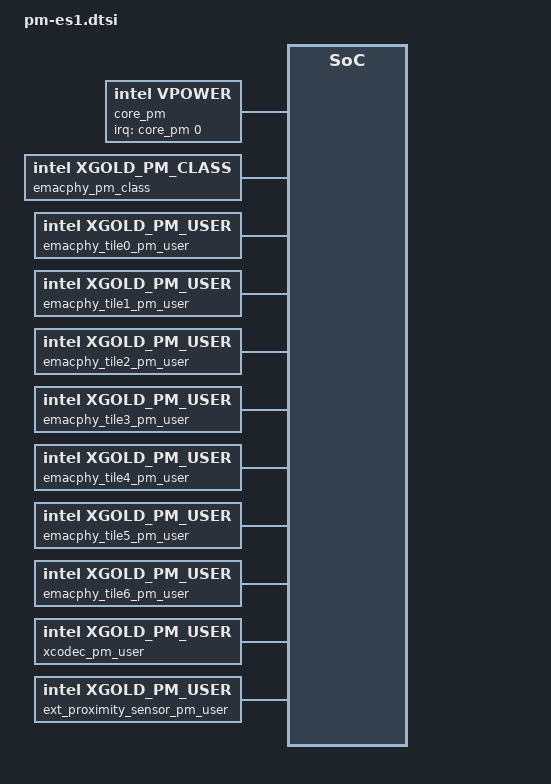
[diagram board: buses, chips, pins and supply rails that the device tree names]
#include "prh_cfg-es1.h"

core_pm:core_pm {
	compatible = "intel,vpower";
	intel,prh_mode = "async";

	#address-cells = < 0 >;
	interrupts = < 0 >;
	interrupt-parent = <&core_pm>;
	#interrupt-cells = < 1 >;
	interrupt-map = < 0 &hirq HIRQ_PMIC_PRH_SIGNALING IRQ_TYPE_DEFAULT>;
	interrupt-names = "notification";
};

generic_pm_class:generic_pm_class {
	compatible = "intel,xgold_pm_class";
	intel,name = "generic_class";
	intel,sync = < 0 0 0 >;
	intel,states-names =
		"disable",
		"enable";
	intel,states = <
		PRH_PER_TYPE_GENERIC PRH_PER_GENERIC_DISABLE
		PRH_PER_TYPE_GENERIC PRH_PER_GENERIC_ENABLE >;
};

mmc_core_clk_pm_class:mmc_core_clk_pm_class {
	compatible = "intel,xgold_pm_class";
	intel,name = "mmc_core_clk_class";
	intel,sync = < 0 0 0 >;
	intel,states-names =
		"low_perf",
		"med_perf",
		"high_perf";
	intel,states = <
		PRH_PER_TYPE_MMC_CORE_CLK PRH_PER_MMC_CORE_CLK_ENABLE_LOW_PERF
		PRH_PER_TYPE_MMC_CORE_CLK PRH_PER_MMC_CORE_CLK_ENABLE_MED_PERF
		PRH_PER_TYPE_MMC_CORE_CLK PRH_PER_MMC_CORE_CLK_ENABLE_HIGH_PERF >;
};

_3g_comram_pm_class:_3g_comram_pm_class {
	compatible = "intel,xgold_pm_class";
	intel,name = "_3g_comram_class";
	intel,sync = < 0 0 0 >;
	intel,states-names =
		"disable",
		"enable",
		"shutdown";
	intel,states = <
		PRH_PER_TYPE_3G_COMRAM PRH_PER_3G_COMRAM_DISABLE
		PRH_PER_TYPE_3G_COMRAM PRH_PER_3G_COMRAM_ENABLE
		PRH_PER_TYPE_3G_COMRAM PRH_PER_3G_COMRAM_SHUTDOWN >;
};

emacphy_pm_class:emacphy_pm_class {
	compatible = "intel,xgold_pm_class";
	intel,name = "emacphy_class";
	intel,sync = < 0 0 0 >;
	intel,states-names =
		"disable",
		"low_perf",
		"mid_perf",
		"high_perf",
		"reset",
		"low_perf_3g";
	intel,states = <
		PRH_PER_TYPE_EMACPHY PRH_PER_EMACPHY_DISABLE
		PRH_PER_TYPE_EMACPHY PRH_PER_EMACPHY_ENABLE_LOW_PERF
		PRH_PER_TYPE_EMACPHY PRH_PER_EMACPHY_ENABLE_MID_PERF
		PRH_PER_TYPE_EMACPHY PRH_PER_EMACPHY_ENABLE_HIGH_PERF
		PRH_PER_TYPE_EMACPHY PRH_PER_EMACPHY_RESET
		PRH_PER_TYPE_EMACPHY PRH_PER_EMACPHY_ENABLE_LOW_PERF_3G >;
};

dma_pm_class:dma_pm_class {
	compatible = "intel,xgold_pm_class";
	intel,name = "dma_class";
	intel,sync = < 0 0 0 >;
	intel,states-names =
		"disable",
		"low_perf",
		"med_perf",
		"high_perf";
	intel,states = <
		PRH_PER_TYPE_DMA PRH_PER_DMA_DISABLE
		PRH_PER_TYPE_DMA PRH_PER_DMA_ENABLE_LOW_PERF
		PRH_PER_TYPE_DMA PRH_PER_DMA_ENABLE_MED_PERF
		PRH_PER_TYPE_DMA PRH_PER_DMA_ENABLE_HIGH_PERF >;
};

dsp_pm_class:dsp_pm_class {
	compatible = "intel,xgold_pm_class";
	intel,name = "dsp_class";
	intel,sync = < 0 0 0 >;
	intel,states-names =
		"disable",
		"enable",
		"suspend",
		"shutdown";
	intel,states = <
		PRH_PER_TYPE_DSP PRH_PER_DSP_DISABLE
		PRH_PER_TYPE_DSP PRH_PER_DSP_ENABLE
		PRH_PER_TYPE_DSP PRH_PER_DSP_SUSPEND
		PRH_PER_TYPE_DSP PRH_PER_DSP_SHUTDOWN >;
};

i2c_pm_class:i2c_pm_class {
	compatible = "intel,xgold_pm_class";
	intel,name = "i2c_class";
	intel,sync = < 0 0 0 >;
	intel,states-names =
		"disable",
		"enable",
		"psv";
	intel,states = <
		PRH_PER_TYPE_I2C PRH_PER_I2C_DISABLE
		PRH_PER_TYPE_I2C PRH_PER_I2C_ENABLE
		PRH_PER_TYPE_I2C PRH_PER_I2C_ENABLE_PSV >;
};

mmcsd_volt_pm_class:mmcsd_volt_pm_class {
	compatible = "intel,xgold_pm_class";
	intel,name = "mmcsd_volt_class";
	intel,sync = < 0 0 0 >;
	intel,states-names =
		"disable",
		"low_perf",
		"mid_perf",
		"high_perf";
	intel,states = <
		PRH_PER_TYPE_MMCSD_VOLT PRH_PER_MMCSD_VOLT_DISABLE
		PRH_PER_TYPE_MMCSD_VOLT PRH_PER_MMCSD_VOLT_ENABLE_LOW
		PRH_PER_TYPE_MMCSD_VOLT PRH_PER_MMCSD_VOLT_ENABLE_MID
		PRH_PER_TYPE_MMCSD_VOLT PRH_PER_MMCSD_VOLT_ENABLE_HIGH >;
};

mmcsd_clk_pm_class:mmcsd_clk_pm_class {
	compatible = "intel,xgold_pm_class";
	intel,name = "mmcsd_clk_class";
	intel,sync = < 0 0 0 >;
	intel,states-names =
		"disable",
		"low_perf",
		"mid_perf",
		"high_perf";
	intel,states = <
		PRH_PER_TYPE_MMCSD_CLK PRH_PER_MMCSD_CLK_DISABLE
		PRH_PER_TYPE_MMCSD_CLK PRH_PER_MMCSD_CLK_ENABLE_LOW
		PRH_PER_TYPE_MMCSD_CLK PRH_PER_MMCSD_CLK_ENABLE_MID
		PRH_PER_TYPE_MMCSD_CLK PRH_PER_MMCSD_CLK_ENABLE_HIGH >;
};

usb_pm_class:usb_pm_class {
	compatible = "intel,xgold_pm_class";
	intel,name = "usb_class";
	intel,sync = < 0 0 0 >;
	intel,states-names =
		"disable",
		"suspend",
		"suspend_no_psv",
		"enable";
	intel,states = <
		PRH_PER_TYPE_USB PRH_PER_USB_DISABLE
		PRH_PER_TYPE_USB PRH_PER_USB_SUSPEND
		PRH_PER_TYPE_USB PRH_PER_USB_SUSPEND_NO_PSV
		PRH_PER_TYPE_USB PRH_PER_USB_ENABLE >;
};

usif_pm_class:usif_pm_class {
	compatible = "intel,xgold_pm_class";
	intel,name = "usif_class";
	intel,sync = < 0 0 0 >;
	intel,states-names =
		"disable",
		"enable_26M",
		"enable_26M_hperf",
		"enable_96M",
		"enable_96M_hperf",
		"enable_104M",
		"enable_104M_hperf";
	intel,states  = <
		PRH_PER_TYPE_USIF PRH_PER_USIF_DISABLE PRH_PER_USIF_CLK_DONT_CARE 0
		PRH_PER_TYPE_USIF PRH_PER_USIF_ENABLE PRH_PER_USIF_CLK_26MHZ 0
		PRH_PER_TYPE_USIF PRH_PER_USIF_ENABLE PRH_PER_USIF_CLK_26MHZ 3173
		PRH_PER_TYPE_USIF PRH_PER_USIF_ENABLE PRH_PER_USIF_CLK_96MHZ 0
		PRH_PER_TYPE_USIF PRH_PER_USIF_ENABLE PRH_PER_USIF_CLK_96MHZ 3173
		PRH_PER_TYPE_USIF PRH_PER_USIF_ENABLE PRH_PER_USIF_CLK_104MHZ 0
		PRH_PER_TYPE_USIF PRH_PER_USIF_ENABLE PRH_PER_USIF_CLK_104MHZ 3173 >;
};

capcom_pm_class:capcom_pm_class {
	compatible = "intel,xgold_pm_class";
	intel,name = "capcom_class";
	intel,sync = < 0 0 0 >;
	intel,states-names =
		"disable",
		"enable",
		"disable_psv",
		"psv";
	intel,states = <
		PRH_PER_TYPE_CAPCOM PRH_PER_CAPCOM_DISABLE
		PRH_PER_TYPE_CAPCOM PRH_PER_CAPCOM_ENABLE
		PRH_PER_TYPE_CAPCOM PRH_PER_CAPCOM_DISABLE_PSV
		PRH_PER_TYPE_CAPCOM PRH_PER_CAPCOM_ENABLE_PSV >;
};

uicc_vcc_pm_class:uicc_vcc_pm_class {
	compatible = "intel,xgold_pm_class";
	intel,name = "uicc_vcc_class";
	intel,sync = < 0 0 0 >;
	intel,states-names =
		"off",
		"class_c",
		"class_b";
	intel,states = <
		PRH_PER_TYPE_UICC_VCC PRH_PER_UICC_VCC_OFF
		PRH_PER_TYPE_UICC_VCC PRH_PER_UICC_VCC_CLASS_C
		PRH_PER_TYPE_UICC_VCC PRH_PER_UICC_VCC_CLASS_B >;
};

uicc_clk_pm_class:uicc_clk_pm_class {
	compatible = "intel,xgold_pm_class";
	intel,name = "uicc_clk_class";
	intel,sync = < 0 0 0 >;
	intel,states-names =
		"disable",
		"suspend",
		"low_perf",
		"med_perf",
		"high_perf";
	intel,states = <
		PRH_PER_TYPE_UICC_CLK PRH_PER_UICC_CLK_DISABLE
		PRH_PER_TYPE_UICC_CLK PRH_PER_UICC_CLK_SUSPEND
		PRH_PER_TYPE_UICC_CLK PRH_PER_UICC_CLK_ENABLE_LOW_PERF
		PRH_PER_TYPE_UICC_CLK PRH_PER_UICC_CLK_ENABLE_MED_PERF
		PRH_PER_TYPE_UICC_CLK PRH_PER_UICC_CLK_ENABLE_HIGH_PERF >;
};

trace_pm_class:trace_pm_class {
	compatible = "intel,xgold_pm_class";
	intel,name = "trace_class";
	intel,sync = < 0 0 0 >;
	intel,states-names =
		"disable",
		"enable",
		"low_perf",
		"med_perf",
		"high_perf",
		"lpt";
	intel,states = <
		PRH_PER_TYPE_TRACE PRH_PER_TRACE_DISABLE
		PRH_PER_TYPE_TRACE PRH_PER_TRACE_ENABLE
		PRH_PER_TYPE_TRACE PRH_PER_TRACE_ENABLE_LOW_PERF
		PRH_PER_TYPE_TRACE PRH_PER_TRACE_ENABLE_MED_PERF
		PRH_PER_TYPE_TRACE PRH_PER_TRACE_ENABLE_HIGH_PERF
		PRH_PER_TYPE_TRACE PRH_PER_TRACE_ENABLE_LPT >;
};

pdb_pm_class:pdb_pm_class {
	compatible = "intel,xgold_pm_class";
	intel,name = "pdb_class";
	intel,sync = < 0 0 0 >;
	intel,states-names =
		"disable",
		"low_perf",
		"med_perf",
		"high_perf";
	intel,states = <
		PRH_PER_TYPE_PDB PRH_PER_PDB_DISABLE
		PRH_PER_TYPE_PDB PRH_PER_PDB_ENABLE_LOW_PERF
		PRH_PER_TYPE_PDB PRH_PER_PDB_ENABLE_MED_PERF
		PRH_PER_TYPE_PDB PRH_PER_PDB_ENABLE_HIGH_PERF >;
};

dcc_pm_class:dcc_pm_class {
	compatible = "intel,xgold_pm_class";
	intel,name = "dcc_class";
	intel,sync = < 0 0 0 >;
	intel,states-names =
		"disable",
		"low_perf",
		"mid_perf",
		"high_perf",
		"ultra_high_perf";
	intel,states = <
		PRH_PER_TYPE_DCC PRH_PER_DCC_DISABLE
		PRH_PER_TYPE_DCC PRH_PER_DCC_ENABLE_LOW_PERF
		PRH_PER_TYPE_DCC PRH_PER_DCC_ENABLE_MID_PERF
		PRH_PER_TYPE_DCC PRH_PER_DCC_ENABLE_HIGH_PERF
		PRH_PER_TYPE_DCC PRH_PER_DCC_ENABLE_ULTRA_HIGH_PERF >;
};

cif_pm_class:cif_pm_class {
	compatible = "intel,xgold_pm_class";
	intel,name = "cif_class";
	intel,sync = < 0 0 0 >;
	intel,states-names =
		"disable",
		"low_perf",
		"mid_perf",
		"high_perf",
		"ultra_high_perf";
	intel,states = <
		PRH_PER_TYPE_CIF PRH_PER_CIF_DISABLE
		PRH_PER_TYPE_CIF PRH_PER_CIF_ENABLE_LOW_PERF
		PRH_PER_TYPE_CIF PRH_PER_CIF_ENABLE_MID_PERF
		PRH_PER_TYPE_CIF PRH_PER_CIF_ENABLE_HIGH_PERF
		PRH_PER_TYPE_CIF PRH_PER_CIF_ENABLE_ULTRA_HIGH_PERF >;
};

kpd_pm_class:kpd_pm_class {
	compatible = "intel,xgold_pm_class";
	intel,name = "kpd_class";
	intel,sync = < 0 0 0 >;
	intel,states-names =
		"disable",
		"enable",
		"psv";
	intel,states = <
		PRH_PER_TYPE_KPD PRH_PER_KPD_DISABLE
		PRH_PER_TYPE_KPD PRH_PER_KPD_ENABLE
		PRH_PER_TYPE_KPD PRH_PER_KPD_ENABLE_PSV >;
};

gpu_pm_class:gpu_pm_class {
	compatible = "intel,xgold_pm_class";
	intel,name = "gpu_class";
	intel,sync = < 0 0 0 >;
	intel,states-names =
		"disable",
		"low_perf",
		"mid_perf",
		"high_perf";
	intel,states = <
		PRH_PER_TYPE_GPU PRH_PER_GPU_DISABLE
		PRH_PER_TYPE_GPU PRH_PER_GPU_ENABLE_LOW_PERF
		PRH_PER_TYPE_GPU PRH_PER_GPU_ENABLE_MID_PERF
		PRH_PER_TYPE_GPU PRH_PER_GPU_ENABLE_HIGH_PERF >;
};

video_dec_pm_class:video_dec_pm_class {
	compatible = "intel,xgold_pm_class";
	intel,name = "video_dec_class";
	intel,sync = < 0 0 0 >;
	intel,states-names =
		"disable",
		"low_perf",
		"mid_perf",
		"high_perf",
		"ultra_high_perf";
	intel,states = <
		PRH_PER_TYPE_VIDEO_DEC PRH_PER_VIDEO_DEC_DISABLE
		PRH_PER_TYPE_VIDEO_DEC PRH_PER_VIDEO_DEC_ENABLE_LOW_PERF
		PRH_PER_TYPE_VIDEO_DEC PRH_PER_VIDEO_DEC_ENABLE_MID_PERF
		PRH_PER_TYPE_VIDEO_DEC PRH_PER_VIDEO_DEC_ENABLE_HIGH_PERF
		PRH_PER_TYPE_VIDEO_DEC PRH_PER_VIDEO_DEC_ENABLE_ULTRA_HIGH_PERF >;
};

video_enc_pm_class:video_enc_pm_class {
	compatible = "intel,xgold_pm_class";
	intel,name = "video_enc_class";
	intel,sync = < 0 0 0 >;
	intel,states-names =
		"disable",
		"low_perf",
		"mid_perf",
		"high_perf",
		"ultra_high_perf";
	intel,states = <
		PRH_PER_TYPE_VIDEO_ENC PRH_PER_VIDEO_ENC_DISABLE
		PRH_PER_TYPE_VIDEO_ENC PRH_PER_VIDEO_ENC_ENABLE_LOW_PERF
		PRH_PER_TYPE_VIDEO_ENC PRH_PER_VIDEO_ENC_ENABLE_MID_PERF
		PRH_PER_TYPE_VIDEO_ENC PRH_PER_VIDEO_ENC_ENABLE_HIGH_PERF
		PRH_PER_TYPE_VIDEO_ENC PRH_PER_VIDEO_ENC_ENABLE_ULTRA_HIGH_PERF >;
};

tdip_pm_class:tdip_pm_class {
	compatible = "intel,xgold_pm_class";
	intel,name = "tdip_class";
	intel,sync = < 0 0 0 >;
	intel,states-names =
		"disable",
		"enable",
		"suspend";
	intel,states = <
		PRH_PER_TYPE_TDIP PRH_PER_TDIP_DISABLE
		PRH_PER_TYPE_TDIP PRH_PER_TDIP_ENABLE
		PRH_PER_TYPE_TDIP PRH_PER_TDIP_SUSPEND >;
};

_3g_subsys_pm_class:_3g_subsys_pm_class {
	compatible = "intel,xgold_pm_class";
	intel,name = "_3g_subsys_class";
	intel,sync = < 0 0 0 >;
	intel,states-names =
		"disable",
		"enable",
		"boot";
	intel,states = <
		PRH_PER_TYPE_3G_SUBSYS PRH_PER_3G_SUBSYS_DISABLE
		PRH_PER_TYPE_3G_SUBSYS PRH_PER_3G_SUBSYS_ENABLE
		PRH_PER_TYPE_3G_SUBSYS PRH_PER_3G_SUBSYS_BOOT >;
};

mmc_core_clk_pm_user:mmc_core_clk_pm_user {
	compatible = "intel,xgold_pm_user";
	intel,name = "mmc_core_clk";
	intel,user-id = <PRH_USER_CPU>;
	intel,per-id = <PRH_PER_MMC_CORE_CLK>;
	intel,class = <&mmc_core_clk_pm_class>;
};

dmac_2ch_pm_user:dmac_2ch_pm_user {
	compatible = "intel,xgold_pm_user";
	intel,name = "dmac_2ch";
	intel,user-id = <PRH_USER_SEC_FRAME>;
	intel,per-id = <PRH_PER_DMAC_2CH>;
	intel,class = <&dma_pm_class>;
};

dmac_2ch_2_pm_user:dmac_2ch_2_pm_user {
	compatible = "intel,xgold_pm_user";
	intel,name = "dmac_2ch_2";
	intel,user-id = <PRH_USER_SEC_FRAME>;
	intel,per-id = <PRH_PER_DMAC_2CH_2>;
	intel,class = <&dma_pm_class>;
};

ceu_pm_user:ceu_pm_user {
	compatible = "intel,xgold_pm_user";
	intel,name = "ceu";
	intel,user-id = <PRH_USER_SEC_FRAME>;
	intel,per-id = <PRH_PER_CEU>;
	intel,class = <&generic_pm_class>;
};

gser_pm_user:gser_pm_user {
	compatible = "intel,xgold_pm_user";
	intel,name = "gser";
	intel,user-id = <PRH_USER_SEC_FRAME>;
	intel,per-id = <PRH_PER_GSER>;
	intel,class = <&generic_pm_class>;
};

_3g_comram_pm_user:_3g_comram_pm_user {
	compatible = "intel,xgold_pm_user";
	intel,name = "_3g_comram";
	intel,user-id = <PRH_USER_3G>;
	intel,per-id = <PRH_PER_3G_COMRAM>;
	intel,class = <&_3g_comram_pm_class>;
};

emacphy_tile0_pm_user:emacphy_tile0_pm_user {
	compatible = "intel,xgold_pm_user";
	intel,name = "emacphy_tile0";
	intel,user-id = <PRH_USER_EMACPHY>;
	intel,per-id = <PRH_PER_EMACPHY_TILE0>;
	intel,class = <&emacphy_pm_class>;
};

emacphy_tile1_pm_user:emacphy_tile1_pm_user {
	compatible = "intel,xgold_pm_user";
	intel,name = "emacphy_tile1";
	intel,user-id = <PRH_USER_EMACPHY>;
	intel,per-id = <PRH_PER_EMACPHY_TILE1>;
	intel,class = <&emacphy_pm_class>;
};

emacphy_tile2_pm_user:emacphy_tile2_pm_user {
	compatible = "intel,xgold_pm_user";
	intel,name = "emacphy_tile2";
	intel,user-id = <PRH_USER_EMACPHY>;
	intel,per-id = <PRH_PER_EMACPHY_TILE2>;
	intel,class = <&emacphy_pm_class>;
};

emacphy_tile3_pm_user:emacphy_tile3_pm_user {
	compatible = "intel,xgold_pm_user";
	intel,name = "emacphy_tile3";
	intel,user-id = <PRH_USER_EMACPHY>;
	intel,per-id = <PRH_PER_EMACPHY_TILE3>;
	intel,class = <&emacphy_pm_class>;
};

emacphy_tile4_pm_user:emacphy_tile4_pm_user {
	compatible = "intel,xgold_pm_user";
	intel,name = "emacphy_tile4";
	intel,user-id = <PRH_USER_EMACPHY>;
	intel,per-id = <PRH_PER_EMACPHY_TILE4>;
	intel,class = <&emacphy_pm_class>;
};

emacphy_tile5_pm_user:emacphy_tile5_pm_user {
	compatible = "intel,xgold_pm_user";
	intel,name = "emacphy_tile5";
	intel,user-id = <PRH_USER_EMACPHY>;
	intel,per-id = <PRH_PER_EMACPHY_TILE5>;
	intel,class = <&emacphy_pm_class>;
};

emacphy_tile6_pm_user:emacphy_tile6_pm_user {
	compatible = "intel,xgold_pm_user";
	intel,name = "emacphy_tile6";
	intel,user-id = <PRH_USER_EMACPHY>;
	intel,per-id = <PRH_PER_EMACPHY_TILE6>;
	intel,class = <&emacphy_pm_class>;
};

ecomram_pm_user:ecomram_pm_user {
	compatible = "intel,xgold_pm_user";
	intel,name = "ecomram";
	intel,user-id = <PRH_USER_EPHY>;
	intel,per-id = <PRH_PER_ECOMRAM>;
	intel,class = <&generic_pm_class>;
};

xb06_dma_pm_user:xb06_dma_pm_user {
	compatible = "intel,xgold_pm_user";
	intel,name = "xb06_dma";
	intel,user-id = <PRH_USER_EPHY>;
	intel,per-id = <PRH_PER_XB06_DMA>;
	intel,class = <&dma_pm_class>;
};

dig_rf_pm_user:dig_rf_pm_user {
	compatible = "intel,xgold_pm_user";
	intel,name = "dig_rf";
	intel,user-id = <PRH_USER_RF>;
	intel,per-id = <PRH_PER_DIG_RF>;
	intel,class = <&generic_pm_class>;
};

dig_rf_aux_pm_user:dig_rf_aux_pm_user {
	compatible = "intel,xgold_pm_user";
	intel,name = "dig_rf_aux";
	intel,user-id = <PRH_USER_RF>;
	intel,per-id = <PRH_PER_DIG_RF_AUX>;
	intel,class = <&generic_pm_class>;
};

gsi_pm_user:gsi_pm_user {
	compatible = "intel,xgold_pm_user";
	intel,name = "gsi";
	intel,user-id = <PRH_USER_RF>;
	intel,per-id = <PRH_PER_GSI>;
	intel,class = <&generic_pm_class>;
};

gsi2_pm_user:gsi2_pm_user {
	compatible = "intel,xgold_pm_user";
	intel,name = "gsi2";
	intel,user-id = <PRH_USER_RF>;
	intel,per-id = <PRH_PER_GSI2>;
	intel,class = <&generic_pm_class>;
};

ahb_per2_rf_bfr_pm_user:ahb_per2_rf_bfr_pm_user {
	compatible = "intel,xgold_pm_user";
	intel,name = "ahb_per2_rf_bfr";
	intel,user-id = <PRH_USER_RF>;
	intel,per-id = <PRH_PER_AHB_PER2_RF_BFR>;
	intel,class = <&generic_pm_class>;
};

ahb_per3_rf_bfr_pm_user:ahb_per3_rf_bfr_pm_user {
	compatible = "intel,xgold_pm_user";
	intel,name = "ahb_per3_rf_bfr";
	intel,user-id = <PRH_USER_RF>;
	intel,per-id = <PRH_PER_AHB_PER3_RF_BFR>;
	intel,class = <&generic_pm_class>;
};

dsp_2g_in_pm_user:dsp_2g_in_pm_user {
	compatible = "intel,xgold_pm_user";
	intel,name = "dsp_2g_in";
	intel,user-id = <PRH_USER_DSP>;
	intel,per-id = <PRH_PER_DSP_2G_IN>;
	intel,class = <&dsp_pm_class>;
};

dsp_2g_out_pm_user:dsp_2g_out_pm_user {
	compatible = "intel,xgold_pm_user";
	intel,name = "dsp_2g_out";
	intel,user-id = <PRH_USER_DSP>;
	intel,per-id = <PRH_PER_DSP_2G_OUT>;
	intel,class = <&dsp_pm_class>;
};

dsp_aud_sample_pm_user:dsp_aud_sample_pm_user {
	compatible = "intel,xgold_pm_user";
	intel,name = "dsp_aud_sample";
	intel,user-id = <PRH_USER_DSP>;
	intel,per-id = <PRH_PER_DSP_AUD_SAMPLE>;
	intel,class = <&dsp_pm_class>;
};

dsp_aud_frame_pm_user:dsp_aud_frame_pm_user {
	compatible = "intel,xgold_pm_user";
	intel,name = "dsp_aud_frame";
	intel,user-id = <PRH_USER_DSP>;
	intel,per-id = <PRH_PER_DSP_AUD_FRAME>;
	intel,class = <&dsp_pm_class>;
};

gps_pm_user:gps_pm_user {
	compatible = "intel,xgold_pm_user";
	intel,name = "gps";
	intel,user-id = <PRH_USER_GPS>;
	intel,per-id = <PRH_PER_GPS>;
	intel,class = <&generic_pm_class>;
};

gps_internal_pm_user:gps_internal_pm_user {
	compatible = "intel,xgold_pm_user";
	intel,name = "gps_internal";
	intel,user-id = <PRH_USER_GPS>;
	intel,per-id = <PRH_PER_GPS_INTERNAL>;
	intel,class = <&generic_pm_class>;
};

aud_psv_pm_user:aud_psv_pm_user {
	compatible = "intel,xgold_pm_user";
	intel,name = "aud_psv";
	intel,user-id = <PRH_USER_AUD_MODEM>;
	intel,per-id = <PRH_PER_AUD_PSV>;
	intel,class = <&generic_pm_class>;
};

i2s1_pm_user:i2s1_pm_user {
	compatible = "intel,xgold_pm_user";
	intel,name = "i2s1";
	intel,user-id = <PRH_USER_AUD_MODEM>;
	intel,per-id = <PRH_PER_I2S1>;
	intel,class = <&generic_pm_class>;
};

i2s2_pm_user:i2s2_pm_user {
	compatible = "intel,xgold_pm_user";
	intel,name = "i2s2";
	intel,user-id = <PRH_USER_AUD_MODEM>;
	intel,per-id = <PRH_PER_I2S2>;
	intel,class = <&generic_pm_class>;
};

xcodec_pm_user:xcodec_pm_user {
	compatible = "intel,xgold_pm_user";
	intel,name = "xcodec";
	intel,user-id = <PRH_USER_AUD_MODEM>;
	intel,per-id = <PRH_PER_XCODEC>;
	intel,class = <&generic_pm_class>;
};

afe_volt_pm_user:afe_volt_pm_user {
	compatible = "intel,xgold_pm_user";
	intel,name = "afe_volt";
	intel,user-id = <PRH_USER_AUD_MODEM>;
	intel,per-id = <PRH_PER_AFE_VOLT>;
	intel,class = <&generic_pm_class>;
};

usb_pm_user:usb_pm_user {
	compatible = "intel,xgold_pm_user";
	intel,name = "usb";
	intel,user-id = <PRH_USER_USB>;
	intel,per-id = <PRH_PER_USB>;
	intel,class = <&usb_pm_class>;
};

ahb_per3_usb_fs_bfr_pm_user:ahb_per3_usb_fs_bfr_pm_user {
	compatible = "intel,xgold_pm_user";
	intel,name = "ahb_per3_usb_fs_bfr";
	intel,user-id = <PRH_USER_USB>;
	intel,per-id = <PRH_PER_AHB_PER3_USB_FS_BFR>;
	intel,class = <&usb_pm_class>;
};

usif1_pm_user:usif1_pm_user {
	compatible = "intel,xgold_pm_user";
	intel,name = "usif1";
	intel,user-id = <PRH_USER_USIF>;
	intel,per-id = <PRH_PER_USIF1>;
	intel,class = <&usif_pm_class>;
};

usif2_pm_user:usif2_pm_user {
	compatible = "intel,xgold_pm_user";
	intel,name = "usif2";
	intel,user-id = <PRH_USER_USIF>;
	intel,per-id = <PRH_PER_USIF2>;
	intel,class = <&usif_pm_class>;
};

usif3_pm_user:usif3_pm_user {
	compatible = "intel,xgold_pm_user";
	intel,name = "usif3";
	intel,user-id = <PRH_USER_USIF>;
	intel,per-id = <PRH_PER_USIF3>;
	intel,class = <&usif_pm_class>;
};

_3g_usif_pm_user:_3g_usif_pm_user {
	compatible = "intel,xgold_pm_user";
	intel,name = "_3g_usif";
	intel,user-id = <PRH_USER_USIF>;
	intel,per-id = <PRH_PER_3G_USIF>;
	intel,class = <&usif_pm_class>;
};

usif4_pm_user:usif4_pm_user {
	compatible = "intel,xgold_pm_user";
	intel,name = "usif4";
	intel,user-id = <PRH_USER_USIF>;
	intel,per-id = <PRH_PER_USIF4>;
	intel,class = <&usif_pm_class>;
};

capcom0_pm_user:capcom0_pm_user {
	compatible = "intel,xgold_pm_user";
	intel,name = "capcom0";
	intel,user-id = <PRH_USER_CAPCOM>;
	intel,per-id = <PRH_PER_CAPCOM0>;
	intel,class = <&capcom_pm_class>;
};

capcom1_pm_user:capcom1_pm_user {
	compatible = "intel,xgold_pm_user";
	intel,name = "capcom1";
	intel,user-id = <PRH_USER_CAPCOM>;
	intel,per-id = <PRH_PER_CAPCOM1>;
	intel,class = <&capcom_pm_class>;
};

capcom2_pm_user:capcom2_pm_user {
	compatible = "intel,xgold_pm_user";
	intel,name = "capcom2";
	intel,user-id = <PRH_USER_CAPCOM>;
	intel,per-id = <PRH_PER_CAPCOM2>;
	intel,class = <&capcom_pm_class>;
};

dmac_8ch_pm_user:dmac_8ch_pm_user {
	compatible = "intel,xgold_pm_user";
	intel,name = "dmac_8ch";
	intel,user-id = <PRH_USER_DMA>;
	intel,per-id = <PRH_PER_DMAC_8CH>;
	intel,class = <&dma_pm_class>;
};

dmac_8ch_2_pm_user:dmac_8ch_2_pm_user {
	compatible = "intel,xgold_pm_user";
	intel,name = "dmac_8ch_2";
	intel,user-id = <PRH_USER_DMA>;
	intel,per-id = <PRH_PER_DMAC_8CH_2>;
	intel,class = <&dma_pm_class>;
};

i2c1_pm_user:i2c1_pm_user {
	compatible = "intel,xgold_pm_user";
	intel,name = "i2c1";
	intel,user-id = <PRH_USER_I2C>;
	intel,per-id = <PRH_PER_I2C1>;
	intel,class = <&i2c_pm_class>;
};

i2c2_pm_user:i2c2_pm_user {
	compatible = "intel,xgold_pm_user";
	intel,name = "i2c2";
	intel,user-id = <PRH_USER_I2C>;
	intel,per-id = <PRH_PER_I2C2>;
	intel,class = <&i2c_pm_class>;
};

i2c3_pm_user:i2c3_pm_user {
	compatible = "intel,xgold_pm_user";
	intel,name = "i2c3";
	intel,user-id = <PRH_USER_I2C>;
	intel,per-id = <PRH_PER_I2C3>;
	intel,class = <&i2c_pm_class>;
};

i2c4_pm_user:i2c4_pm_user {
	compatible = "intel,xgold_pm_user";
	intel,name = "i2c4";
	intel,user-id = <PRH_USER_I2C>;
	intel,per-id = <PRH_PER_I2C4>;
	intel,class = <&i2c_pm_class>;
};

i2c5_pm_user:i2c5_pm_user {
	compatible = "intel,xgold_pm_user";
	intel,name = "i2c5";
	intel,user-id = <PRH_USER_I2C>;
	intel,per-id = <PRH_PER_I2C5>;
	intel,class = <&i2c_pm_class>;
};

pcl_pm_user:pcl_pm_user {
	compatible = "intel,xgold_pm_user";
	intel,name = "pcl";
	intel,user-id = <PRH_USER_PCL>;
	intel,per-id = <PRH_PER_PCL>;
	intel,class = <&generic_pm_class>;
};

gptu0_pm_user:gptu0_pm_user {
	compatible = "intel,xgold_pm_user";
	intel,name = "gptu0";
	intel,user-id = <PRH_USER_TS>;
	intel,per-id = <PRH_PER_GPTU0>;
	intel,class = <&generic_pm_class>;
};

gptu1_pm_user:gptu1_pm_user {
	compatible = "intel,xgold_pm_user";
	intel,name = "gptu1";
	intel,user-id = <PRH_USER_TS>;
	intel,per-id = <PRH_PER_GPTU1>;
	intel,class = <&generic_pm_class>;
};

stm_pm_user:stm_pm_user {
	compatible = "intel,xgold_pm_user";
	intel,name = "stm";
	intel,user-id = <PRH_USER_TS>;
	intel,per-id = <PRH_PER_STM>;
	intel,class = <&generic_pm_class>;
};

rtc_pm_user:rtc_pm_user {
	compatible = "intel,xgold_pm_user";
	intel,name = "rtc";
	intel,user-id = <PRH_USER_RTC>;
	intel,per-id = <PRH_PER_RTC>;
	intel,class = <&generic_pm_class>;
};

tsmu_pm_user:tsmu_pm_user {
	compatible = "intel,xgold_pm_user";
	intel,name = "tsmu";
	intel,user-id = <PRH_USER_MEAS>;
	intel,per-id = <PRH_PER_TSMU>;
	intel,class = <&generic_pm_class>;
};

uicc_vcc_pm_user:uicc_vcc_pm_user {
	compatible = "intel,xgold_pm_user";
	intel,name = "uicc_vcc";
	intel,user-id = <PRH_USER_UICC>;
	intel,per-id = <PRH_PER_UICC_VCC>;
	intel,class = <&uicc_vcc_pm_class>;
};

uicc_clk_pm_user:uicc_clk_pm_user {
	compatible = "intel,xgold_pm_user";
	intel,name = "uicc_clk";
	intel,user-id = <PRH_USER_UICC>;
	intel,per-id = <PRH_PER_UICC_CLK>;
	intel,class = <&uicc_clk_pm_class>;
};

uicc2_vcc_pm_user:uicc2_vcc_pm_user {
	compatible = "intel,xgold_pm_user";
	intel,name = "uicc2_vcc";
	intel,user-id = <PRH_USER_UICC>;
	intel,per-id = <PRH_PER_UICC2_VCC>;
	intel,class = <&uicc_vcc_pm_class>;
};

uicc2_clk_pm_user:uicc2_clk_pm_user {
	compatible = "intel,xgold_pm_user";
	intel,name = "uicc2_clk";
	intel,user-id = <PRH_USER_UICC>;
	intel,per-id = <PRH_PER_UICC2_CLK>;
	intel,class = <&uicc_clk_pm_class>;
};

sdmmc1_volt_pm_user:sdmmc1_volt_pm_user {
	compatible = "intel,xgold_pm_user";
	intel,name = "sdmmc1_volt";
	intel,user-id = <PRH_USER_MMCSD>;
	intel,per-id = <PRH_PER_SDMMC1_VOLT>;
	intel,class = <&mmcsd_volt_pm_class>;
};

sdmmc1_clk_pm_user:sdmmc1_clk_pm_user {
	compatible = "intel,xgold_pm_user";
	intel,name = "sdmmc1_clk";
	intel,user-id = <PRH_USER_MMCSD>;
	intel,per-id = <PRH_PER_SDMMC1_CLK>;
	intel,class = <&mmcsd_clk_pm_class>;
};

sdmmc1_pow_pm_user:sdmmc1_pow_pm_user {
	compatible = "intel,xgold_pm_user";
	intel,name = "sdmmc1_pow";
	intel,user-id = <PRH_USER_MMCSD>;
	intel,per-id = <PRH_PER_SDMMC1_POW>;
	intel,class = <&generic_pm_class>;
};

sdmmc1_psv_pm_user:sdmmc1_psv_pm_user {
	compatible = "intel,xgold_pm_user";
	intel,name = "sdmmc1_psv";
	intel,user-id = <PRH_USER_MMCSD>;
	intel,per-id = <PRH_PER_SDMMC1_PSV>;
	intel,class = <&generic_pm_class>;
};

sdio_volt_pm_user:sdio_volt_pm_user {
	compatible = "intel,xgold_pm_user";
	intel,name = "sdio_volt";
	intel,user-id = <PRH_USER_MMCSD>;
	intel,per-id = <PRH_PER_SDIO_VOLT>;
	intel,class = <&mmcsd_volt_pm_class>;
};

sdio_clk_pm_user:sdio_clk_pm_user {
	compatible = "intel,xgold_pm_user";
	intel,name = "sdio_clk";
	intel,user-id = <PRH_USER_MMCSD>;
	intel,per-id = <PRH_PER_SDIO_CLK>;
	intel,class = <&mmcsd_clk_pm_class>;
};

sdio_pow_pm_user:sdio_pow_pm_user {
	compatible = "intel,xgold_pm_user";
	intel,name = "sdio_pow";
	intel,user-id = <PRH_USER_MMCSD>;
	intel,per-id = <PRH_PER_SDIO_POW>;
	intel,class = <&generic_pm_class>;
};

sdio_psv_pm_user:sdio_psv_pm_user {
	compatible = "intel,xgold_pm_user";
	intel,name = "sdio_psv";
	intel,user-id = <PRH_USER_MMCSD>;
	intel,per-id = <PRH_PER_SDIO_PSV>;
	intel,class = <&generic_pm_class>;
};

vemmc_volt_pm_user:vemmc_volt_pm_user {
	compatible = "intel,xgold_pm_user";
	intel,name = "vemmc_volt";
	intel,user-id = <PRH_USER_MMCSD>;
	intel,per-id = <PRH_PER_VEMMC_VOLT>;
	intel,class = <&mmcsd_volt_pm_class>;
};

emmc_clk_pm_user:emmc_clk_pm_user {
	compatible = "intel,xgold_pm_user";
	intel,name = "emmc_clk";
	intel,user-id = <PRH_USER_MMCSD>;
	intel,per-id = <PRH_PER_EMMC_CLK>;
	intel,class = <&mmcsd_clk_pm_class>;
};

emmc_pow_pm_user:emmc_pow_pm_user {
	compatible = "intel,xgold_pm_user";
	intel,name = "emmc_pow";
	intel,user-id = <PRH_USER_MMCSD>;
	intel,per-id = <PRH_PER_EMMC_POW>;
	intel,class = <&generic_pm_class>;
};

emmc_psv_pm_user:emmc_psv_pm_user {
	compatible = "intel,xgold_pm_user";
	intel,name = "emmc_psv";
	intel,user-id = <PRH_USER_MMCSD>;
	intel,per-id = <PRH_PER_EMMC_PSV>;
	intel,class = <&generic_pm_class>;
};

st_arb_pm_user:st_arb_pm_user {
	compatible = "intel,xgold_pm_user";
	intel,name = "st_arb";
	intel,user-id = <PRH_USER_TRACE>;
	intel,per-id = <PRH_PER_ST_ARB>;
	intel,class = <&trace_pm_class>;
};

st_oct_pm_user:st_oct_pm_user {
	compatible = "intel,xgold_pm_user";
	intel,name = "st_oct";
	intel,user-id = <PRH_USER_TRACE>;
	intel,per-id = <PRH_PER_ST_OCT>;
	intel,class = <&trace_pm_class>;
};

st_oct_dvc_pm_user:st_oct_dvc_pm_user {
	compatible = "intel,xgold_pm_user";
	intel,name = "st_oct_dvc";
	intel,user-id = <PRH_USER_TRACE>;
	intel,per-id = <PRH_PER_ST_OCT_DVC>;
	intel,class = <&trace_pm_class>;
};

st_mtm1_pm_user:st_mtm1_pm_user {
	compatible = "intel,xgold_pm_user";
	intel,name = "st_mtm1";
	intel,user-id = <PRH_USER_TRACE>;
	intel,per-id = <PRH_PER_ST_MTM1>;
	intel,class = <&trace_pm_class>;
};

st_mtm2_pm_user:st_mtm2_pm_user {
	compatible = "intel,xgold_pm_user";
	intel,name = "st_mtm2";
	intel,user-id = <PRH_USER_TRACE>;
	intel,per-id = <PRH_PER_ST_MTM2>;
	intel,class = <&trace_pm_class>;
};

st_mtm2_pad_pm_user:st_mtm2_pad_pm_user {
	compatible = "intel,xgold_pm_user";
	intel,name = "st_mtm2_pad";
	intel,user-id = <PRH_USER_TRACE>;
	intel,per-id = <PRH_PER_ST_MTM2_PAD>;
	intel,class = <&trace_pm_class>;
};

st_mon_pm_user:st_mon_pm_user {
	compatible = "intel,xgold_pm_user";
	intel,name = "st_mon";
	intel,user-id = <PRH_USER_TRACE>;
	intel,per-id = <PRH_PER_ST_MON>;
	intel,class = <&trace_pm_class>;
};

st_mon_sb_1_pm_user:st_mon_sb_1_pm_user {
	compatible = "intel,xgold_pm_user";
	intel,name = "st_mon_sb_1";
	intel,user-id = <PRH_USER_TRACE>;
	intel,per-id = <PRH_PER_ST_MON_SB_1>;
	intel,class = <&trace_pm_class>;
};

st_mon_sb_2_pm_user:st_mon_sb_2_pm_user {
	compatible = "intel,xgold_pm_user";
	intel,name = "st_mon_sb_2";
	intel,user-id = <PRH_USER_TRACE>;
	intel,per-id = <PRH_PER_ST_MON_SB_2>;
	intel,class = <&trace_pm_class>;
};

st_mon_sb_3_pm_user:st_mon_sb_3_pm_user {
	compatible = "intel,xgold_pm_user";
	intel,name = "st_mon_sb_3";
	intel,user-id = <PRH_USER_TRACE>;
	intel,per-id = <PRH_PER_ST_MON_SB_3>;
	intel,class = <&trace_pm_class>;
};

st_mon_sb_4_pm_user:st_mon_sb_4_pm_user {
	compatible = "intel,xgold_pm_user";
	intel,name = "st_mon_sb_4";
	intel,user-id = <PRH_USER_TRACE>;
	intel,per-id = <PRH_PER_ST_MON_SB_4>;
	intel,class = <&trace_pm_class>;
};

st_mon_sb_5_pm_user:st_mon_sb_5_pm_user {
	compatible = "intel,xgold_pm_user";
	intel,name = "st_mon_sb_5";
	intel,user-id = <PRH_USER_TRACE>;
	intel,per-id = <PRH_PER_ST_MON_SB_5>;
	intel,class = <&trace_pm_class>;
};

st_mon_sb_6_pm_user:st_mon_sb_6_pm_user {
	compatible = "intel,xgold_pm_user";
	intel,name = "st_mon_sb_6";
	intel,user-id = <PRH_USER_TRACE>;
	intel,per-id = <PRH_PER_ST_MON_SB_6>;
	intel,class = <&trace_pm_class>;
};

st_mon_sb_7_pm_user:st_mon_sb_7_pm_user {
	compatible = "intel,xgold_pm_user";
	intel,name = "st_mon_sb_7";
	intel,user-id = <PRH_USER_TRACE>;
	intel,per-id = <PRH_PER_ST_MON_SB_7>;
	intel,class = <&trace_pm_class>;
};

st_mon_sb_8_pm_user:st_mon_sb_8_pm_user {
	compatible = "intel,xgold_pm_user";
	intel,name = "st_mon_sb_8";
	intel,user-id = <PRH_USER_TRACE>;
	intel,per-id = <PRH_PER_ST_MON_SB_8>;
	intel,class = <&trace_pm_class>;
};

st_mon_sb_9_pm_user:st_mon_sb_9_pm_user {
	compatible = "intel,xgold_pm_user";
	intel,name = "st_mon_sb_9";
	intel,user-id = <PRH_USER_TRACE>;
	intel,per-id = <PRH_PER_ST_MON_SB_9>;
	intel,class = <&trace_pm_class>;
};

st_mon_sb_10_pm_user:st_mon_sb_10_pm_user {
	compatible = "intel,xgold_pm_user";
	intel,name = "st_mon_sb_10";
	intel,user-id = <PRH_USER_TRACE>;
	intel,per-id = <PRH_PER_ST_MON_SB_10>;
	intel,class = <&trace_pm_class>;
};

st_mon_sb_11_pm_user:st_mon_sb_11_pm_user {
	compatible = "intel,xgold_pm_user";
	intel,name = "st_mon_sb_11";
	intel,user-id = <PRH_USER_TRACE>;
	intel,per-id = <PRH_PER_ST_MON_SB_11>;
	intel,class = <&trace_pm_class>;
};

st_mon_sb_12_pm_user:st_mon_sb_12_pm_user {
	compatible = "intel,xgold_pm_user";
	intel,name = "st_mon_sb_12";
	intel,user-id = <PRH_USER_TRACE>;
	intel,per-id = <PRH_PER_ST_MON_SB_12>;
	intel,class = <&trace_pm_class>;
};

st_mon_sb_13_pm_user:st_mon_sb_13_pm_user {
	compatible = "intel,xgold_pm_user";
	intel,name = "st_mon_sb_13";
	intel,user-id = <PRH_USER_TRACE>;
	intel,per-id = <PRH_PER_ST_MON_SB_13>;
	intel,class = <&trace_pm_class>;
};

st_mon_sb_14_pm_user:st_mon_sb_14_pm_user {
	compatible = "intel,xgold_pm_user";
	intel,name = "st_mon_sb_14";
	intel,user-id = <PRH_USER_TRACE>;
	intel,per-id = <PRH_PER_ST_MON_SB_14>;
	intel,class = <&trace_pm_class>;
};

st_mon_sb_16_pm_user:st_mon_sb_16_pm_user {
	compatible = "intel,xgold_pm_user";
	intel,name = "st_mon_sb_16";
	intel,user-id = <PRH_USER_TRACE>;
	intel,per-id = <PRH_PER_ST_MON_SB_16>;
	intel,class = <&trace_pm_class>;
};

etm3g_pm_user:etm3g_pm_user {
	compatible = "intel,xgold_pm_user";
	intel,name = "etm3g";
	intel,user-id = <PRH_USER_TRACE>;
	intel,per-id = <PRH_PER_ETM3G>;
	intel,class = <&trace_pm_class>;
};

cst_pm_user:cst_pm_user {
	compatible = "intel,xgold_pm_user";
	intel,name = "cst";
	intel,user-id = <PRH_USER_TRACE>;
	intel,per-id = <PRH_PER_CST>;
	intel,class = <&trace_pm_class>;
};

fspeed_psv_pm_user:fspeed_psv_pm_user {
	compatible = "intel,xgold_pm_user";
	intel,name = "fspeed_psv";
	intel,user-id = <PRH_USER_FSPEED>;
	intel,per-id = <PRH_PER_FSPEED_PSV>;
	intel,class = <&generic_pm_class>;
};

fspeed_low_volt_pm_user:fspeed_low_volt_pm_user {
	compatible = "intel,xgold_pm_user";
	intel,name = "fspeed_low_volt";
	intel,user-id = <PRH_USER_FSPEED>;
	intel,per-id = <PRH_PER_FSPEED_LOW_VOLT>;
	intel,class = <&generic_pm_class>;
};

ext_xg639_pm_user:ext_xg639_pm_user {
	compatible = "intel,xgold_pm_user";
	intel,name = "ext_xg639";
	intel,user-id = <PRH_USER_TDS_PS>;
	intel,per-id = <PRH_PER_EXT_XG639>;
	intel,class = <&generic_pm_class>;
};

_3g_pm_user:_3g_pm_user {
	compatible = "intel,xgold_pm_user";
	intel,name = "_3g";
	intel,user-id = <PRH_USER_TDS_PS>;
	intel,per-id = <PRH_PER_3G>;
	intel,class = <&generic_pm_class>;
};

tdip_pm_user:tdip_pm_user {
	compatible = "intel,xgold_pm_user";
	intel,name = "tdip";
	intel,user-id = <PRH_USER_TDS_PS>;
	intel,per-id = <PRH_PER_TDIP>;
	intel,class = <&tdip_pm_class>;
};

tds_comram_pm_user:tds_comram_pm_user {
	compatible = "intel,xgold_pm_user";
	intel,name = "tds_comram";
	intel,user-id = <PRH_USER_TDS_PS>;
	intel,per-id = <PRH_PER_TDS_COMRAM>;
	intel,class = <&generic_pm_class>;
};

_3g_subsys_pm_user:_3g_subsys_pm_user {
	compatible = "intel,xgold_pm_user";
	intel,name = "_3g_subsys";
	intel,user-id = <PRH_USER_TDS_PS>;
	intel,per-id = <PRH_PER_3G_SUBSYS>;
	intel,class = <&_3g_subsys_pm_class>;
};

pdb_pm_user:pdb_pm_user {
	compatible = "intel,xgold_pm_user";
	intel,name = "pdb";
	intel,user-id = <PRH_USER_PDB>;
	intel,per-id = <PRH_PER_PDB>;
	intel,class = <&pdb_pm_class>;
};

lte_pm_user:lte_pm_user {
	compatible = "intel,xgold_pm_user";
	intel,name = "lte";
	intel,user-id = <PRH_USER_L1U>;
	intel,per-id = <PRH_PER_LTE>;
	intel,class = <&generic_pm_class>;
};

cif_pm_user:cif_pm_user {
	compatible = "intel,xgold_pm_user";
	intel,name = "cif";
	intel,user-id = <PRH_USER_CAMERA>;
	intel,per-id = <PRH_PER_CIF>;
	intel,class = <&cif_pm_class>;
};

ext_prim_cam_pm_user:ext_prim_cam_pm_user {
	compatible = "intel,xgold_pm_user";
	intel,name = "ext_prim_cam";
	intel,user-id = <PRH_USER_CAMERA>;
	intel,per-id = <PRH_PER_EXT_PRIM_CAM>;
	intel,class = <&generic_pm_class>;
};

ext_sec_cam_pm_user:ext_sec_cam_pm_user {
	compatible = "intel,xgold_pm_user";
	intel,name = "ext_sec_cam";
	intel,user-id = <PRH_USER_CAMERA>;
	intel,per-id = <PRH_PER_EXT_SEC_CAM>;
	intel,class = <&generic_pm_class>;
};

kpd_pm_user:kpd_pm_user {
	compatible = "intel,xgold_pm_user";
	intel,name = "kpd";
	intel,user-id = <PRH_USER_KPD>;
	intel,per-id = <PRH_PER_KPD>;
	intel,class = <&kpd_pm_class>;
};

gpu_pm_user:gpu_pm_user {
	compatible = "intel,xgold_pm_user";
	intel,name = "gpu";
	intel,user-id = <PRH_USER_GPU>;
	intel,per-id = <PRH_PER_GPU>;
	intel,class = <&gpu_pm_class>;
};

video_dec_pm_user:video_dec_pm_user {
	compatible = "intel,xgold_pm_user";
	intel,name = "video_dec";
	intel,user-id = <PRH_USER_VPU_DEC>;
	intel,per-id = <PRH_PER_VIDEO_DEC>;
	intel,class = <&video_dec_pm_class>;
};

video_enc_pm_user:video_enc_pm_user {
	compatible = "intel,xgold_pm_user";
	intel,name = "video_enc";
	intel,user-id = <PRH_USER_VPU_ENC>;
	intel,per-id = <PRH_PER_VIDEO_ENC>;
	intel,class = <&video_enc_pm_class>;
};

ext_tp_pm_user:ext_tp_pm_user {
	compatible = "intel,xgold_pm_user";
	intel,name = "ext_tp";
	intel,user-id = <PRH_USER_TP>;
	intel,per-id = <PRH_PER_EXT_TP>;
	intel,class = <&generic_pm_class>;
};

ext_accelerometer_pm_user:ext_accelerometer_pm_user {
	compatible = "intel,xgold_pm_user";
	intel,name = "ext_accelerometer";
	intel,user-id = <PRH_USER_ACCELEROMETER>;
	intel,per-id = <PRH_PER_EXT_ACCELEROMETER>;
	intel,class = <&generic_pm_class>;
};

ext_proximity_sensor_pm_user:ext_proximity_sensor_pm_user {
	compatible = "intel,xgold_pm_user";
	intel,name = "ext_proximity_sensor";
	intel,user-id = <PRH_USER_PROXIMITY_SENSOR>;
	intel,per-id = <PRH_PER_EXT_PROXIMITY_SENSOR>;
	intel,class = <&generic_pm_class>;
};

ext_gyroscope_pm_user:ext_gyroscope_pm_user {
	compatible = "intel,xgold_pm_user";
	intel,name = "ext_gyroscope";
	intel,user-id = <PRH_USER_GYROSCOPE>;
	intel,per-id = <PRH_PER_EXT_GYROSCOPE>;
	intel,class = <&generic_pm_class>;
};

dcc_pm_user:dcc_pm_user {
	compatible = "intel,xgold_pm_user";
	intel,name = "dcc";
	intel,user-id = <PRH_USER_DISPLAY>;
	intel,per-id = <PRH_PER_DCC>;
	intel,class = <&dcc_pm_class>;
};

ext_display_pm_user:ext_display_pm_user {
	compatible = "intel,xgold_pm_user";
	intel,name = "ext_display";
	intel,user-id = <PRH_USER_DISPLAY>;
	intel,per-id = <PRH_PER_EXT_DISPLAY>;
	intel,class = <&generic_pm_class>;
};

ext_magnetometer_pm_user:ext_magnetometer_pm_user {
	compatible = "intel,xgold_pm_user";
	intel,name = "ext_magnetometer";
	intel,user-id = <PRH_USER_MAGNETOMETER>;
	intel,per-id = <PRH_PER_EXT_MAGNETOMETER>;
	intel,class = <&generic_pm_class>;
};

